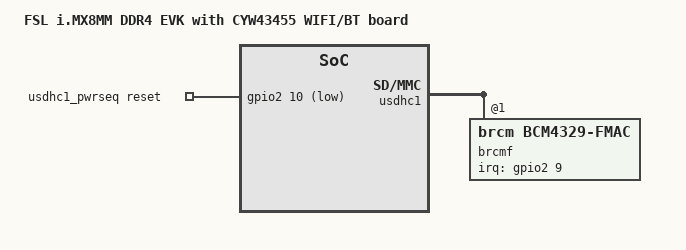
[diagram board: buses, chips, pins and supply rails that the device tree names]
// SPDX-License-Identifier: GPL-2.0+
/*
 * Copyright 2018 NXP
 */

/dts-v1/;

#include "fsl-imx8mm-ddr4-evk.dts"

/ {
	model = "FSL i.MX8MM DDR4 EVK with CYW43455 WIFI/BT board";

	usdhc1_pwrseq: usdhc1_pwrseq {
		compatible = "mmc-pwrseq-simple";
		pinctrl-names = "default";
		pinctrl-0 = <&pinctrl_usdhc1_gpio>;
		reset-gpios = <&gpio2 10 GPIO_ACTIVE_LOW>;
	};
};

&iomuxc {
	imx8mm-evk {
		pinctrl_wlan: wlangrp {
			fsl,pins = <
				MX8MM_IOMUXC_GPIO1_IO00_ANAMIX_REF_CLK_32K	0x141
				MX8MM_IOMUXC_SD1_DATA7_GPIO2_IO9		0x111
			>;
		};
	};
};

&reg_sd1_vmmc {
	status = "disabled";
};

&usdhc1 {
	#address-cells = <1>;
	#size-cells = <0>;
	pinctrl-0 = <&pinctrl_usdhc1>, <&pinctrl_wlan>;
	pinctrl-1 = <&pinctrl_usdhc1_100mhz>, <&pinctrl_wlan>;
	pinctrl-2 = <&pinctrl_usdhc1_200mhz>, <&pinctrl_wlan>;
	cap-power-off-card;
	/delete-property/ vmmc-supply;
	mmc-pwrseq = <&usdhc1_pwrseq>;

	brcmf: bcrmf@1 {
		reg = <1>;
		compatible = "brcm,bcm4329-fmac";
		interrupt-parent = <&gpio2>;
		interrupts = <9 IRQ_TYPE_LEVEL_HIGH>;
		interrupt-names = "host-wake";
	};
};
